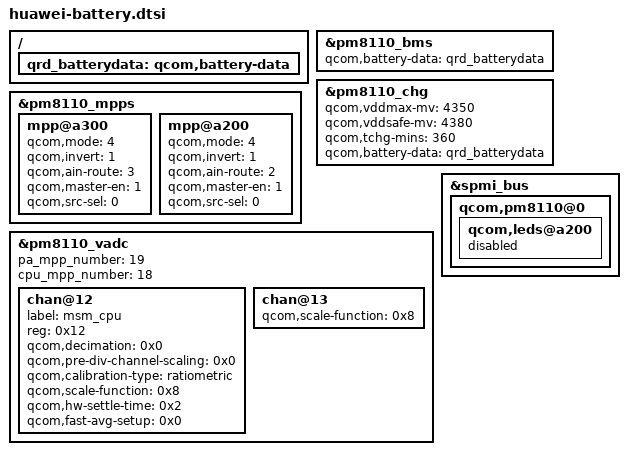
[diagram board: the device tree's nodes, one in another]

/ {
        qrd_batterydata: qcom,battery-data {
                /include/ "HB474284RBC_BYD-4v35-2000mah.dtsi"
        };
};

&pm8110_bms {
	qcom,battery-data = <&qrd_batterydata>;
};

&pm8110_chg {
	status = "okay";
	qcom,vddmax-mv = <4350>;
	qcom,vddsafe-mv = <4380>;
	qcom,tchg-mins = <360>;
	qcom,battery-data = <&qrd_batterydata>;
};
&pm8110_mpps {
	mpp@a300 {
		status = "okay";
		qcom,mode = <4>; 
		qcom,invert = <1>;
		qcom,ain-route = <3>;
		qcom,master-en = <1>;
		qcom,src-sel = <0>;
	};
	mpp@a200 {
		status = "okay";
		qcom,mode = <4>;
		qcom,invert = <1>;
		qcom,ain-route = <2>;
		qcom,master-en = <1>;
		qcom,src-sel = <0>;
	};	

};
&pm8110_vadc {
	pa_mpp_number = <19>;
	cpu_mpp_number = <18>;
	
	chan@12 {
		label = "msm_cpu";
		reg = <0x12>;
		qcom,decimation = <0x0>;
		qcom,pre-div-channel-scaling = <0x0>;
		qcom,calibration-type = "ratiometric";
		qcom,scale-function = <0x8>;
		qcom,hw-settle-time = <0x2>;
		qcom,fast-avg-setup = <0x0>;
	};
	chan@13 {
		qcom,scale-function = <0x8>;
	};
};

&spmi_bus {
	qcom,pm8110@0 {
		qcom,leds@a200 {
			status = "disabled";
		};
	};
};
